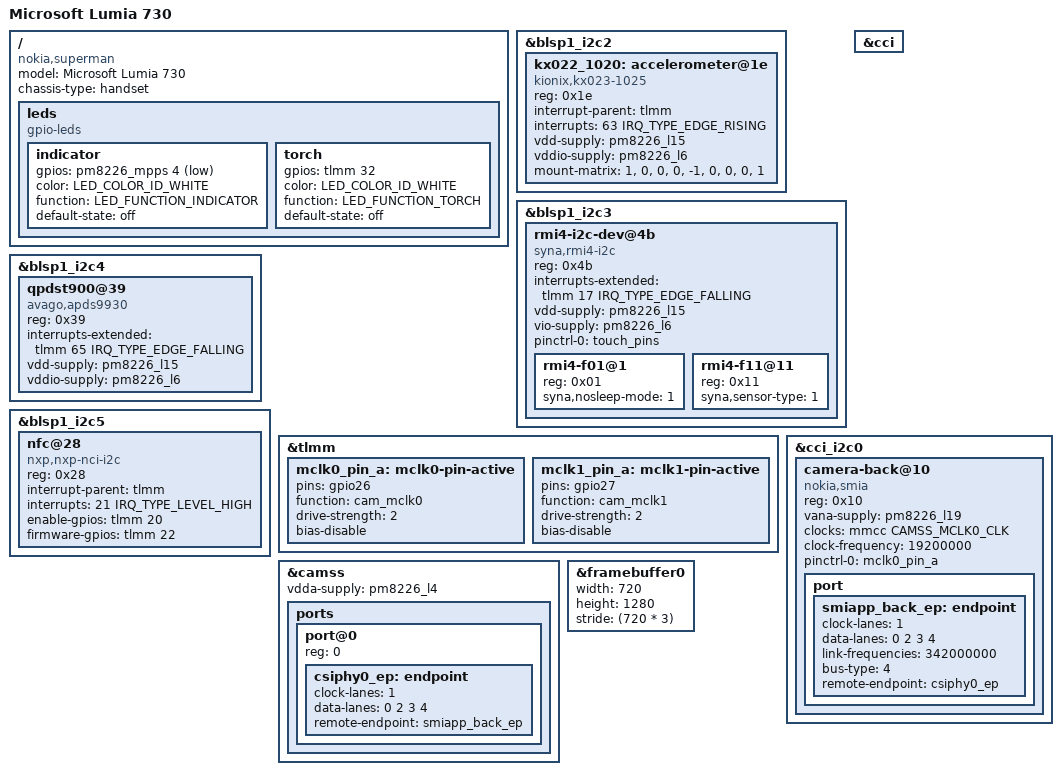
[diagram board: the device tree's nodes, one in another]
// SPDX-License-Identifier: BSD-3-Clause
/*
 * Copyright (c) 2022, Jack Matthews <jm5112356@gmail.com>
 * Copyright (c) 2022, Ivaylo Ivanov <ivo.ivanov.ivanov1@gmail.com>
 * Copyright (c) 2022, Dominik Kobinski <dominikkobinski314@gmail.com>
 * Copyright (c) 2022, Rayyan Ansari <rayyan@ansari.sh>
 */

/dts-v1/;

#include "qcom-msm8226-nokia-common.dtsi"
#include <dt-bindings/leds/common.h>

/ {
	model = "Microsoft Lumia 730";
	compatible = "nokia,superman","qcom,msm8226";
	chassis-type = "handset";

	leds {
		compatible = "gpio-leds";

		indicator {
			gpios = <&pm8226_mpps 4 GPIO_ACTIVE_LOW>;
			color = <LED_COLOR_ID_WHITE>;
			function = LED_FUNCTION_INDICATOR;
			default-state = "off";
		};

		torch {
			gpios = <&tlmm 32 GPIO_ACTIVE_HIGH>;
			color = <LED_COLOR_ID_WHITE>;
			function = LED_FUNCTION_TORCH;
			default-state = "off";
		};
	};
};

&blsp1_i2c2 {
	status = "okay";

	kx022_1020: accelerometer@1e {
		/*
		 * This is actually the Kionix KX022-1020, but the KX023-1025 driver
		 * seems to work fine for now.
		 */
		compatible = "kionix,kx023-1025";
		reg = <0x1e>;

		interrupt-parent = <&tlmm>;
		interrupts = <63 IRQ_TYPE_EDGE_RISING>;

		vdd-supply = <&pm8226_l15>;
		vddio-supply = <&pm8226_l6>;

		mount-matrix =  "1",  "0",  "0",
						"0", "-1",  "0",
						"0",  "0",  "1";
	};
};

&blsp1_i2c3 {
	status = "okay";

	rmi4-i2c-dev@4b {
		compatible = "syna,rmi4-i2c";
		reg = <0x4b>;
		#address-cells = <1>;
		#size-cells = <0>;

		interrupts-extended = <&tlmm 17 IRQ_TYPE_EDGE_FALLING>;
		vdd-supply = <&pm8226_l15>;
		vio-supply = <&pm8226_l6>;

		pinctrl-names = "default";
		pinctrl-0 = <&touch_pins>;

		rmi4-f01@1 {
			reg = <0x01>;
			syna,nosleep-mode = <1>;
		};

		rmi4-f11@11 {
			reg = <0x11>;
			syna,sensor-type = <1>;
		};
	};
};

&blsp1_i2c4 {
	status = "okay";

	qpdst900@39 {
		compatible = "avago,apds9930";
		reg = <0x39>;

		interrupts-extended = <&tlmm 65 IRQ_TYPE_EDGE_FALLING>;

		vdd-supply = <&pm8226_l15>;
		vddio-supply = <&pm8226_l6>;

	};
};

&blsp1_i2c5 {
	status = "okay";

	nfc@28 {
		compatible = "nxp,nxp-nci-i2c";
		reg = <0x28>;

		interrupt-parent = <&tlmm>;
		interrupts = <21 IRQ_TYPE_LEVEL_HIGH>;

		enable-gpios = <&tlmm 20 GPIO_ACTIVE_HIGH>;
		firmware-gpios = <&tlmm 22 GPIO_ACTIVE_HIGH>;
	};
};

&tlmm {
	mclk0_pin_a: mclk0-pin-active {
		pins = "gpio26";
		function = "cam_mclk0";

		drive-strength = <2>;
		bias-disable;
	};

	mclk1_pin_a: mclk1-pin-active {
		pins = "gpio27";
		function = "cam_mclk1";

		drive-strength = <2>;
		bias-disable;
	};
};

&cci {
	status = "okay";
};

&cci_i2c0 {
	camera-back@10 {
		compatible = "nokia,smia";
		reg = <0x10>;

		vana-supply = <&pm8226_l19>;
		clocks = <&mmcc CAMSS_MCLK0_CLK>;
		clock-frequency = <19200000>;

		pinctrl-names = "default";
		pinctrl-0 = <&mclk0_pin_a>;

		port {
			smiapp_back_ep: endpoint {
				clock-lanes = <1>;
				data-lanes = <0 2 3 4>;
				link-frequencies = /bits/ 64 <342000000>; 
				bus-type = <4>;
				remote-endpoint = <&csiphy0_ep>;
			};
		};

	};
};

&camss {
	status = "okay";

	vdda-supply = <&pm8226_l4>;

	ports {
		#address-cells = <1>;
		#size-cells = <0>;
		port@0 {
			reg = <0>;
			csiphy0_ep: endpoint {
				clock-lanes = <1>;
				data-lanes = <0 2 3 4>;
				remote-endpoint = <&smiapp_back_ep>;
			};
		};
	};
};

&framebuffer0 {
	width = <720>;
	height = <1280>;
	stride = <(720 * 3)>;
};
